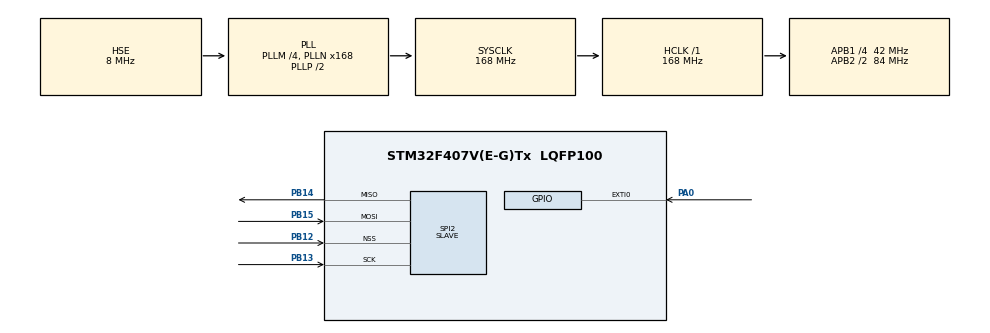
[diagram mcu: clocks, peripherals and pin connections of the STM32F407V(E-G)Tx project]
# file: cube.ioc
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Dma.Request0=SPI2_RX
Dma.Request1=SPI2_TX
Dma.SPI2_RX.0.Direction=DMA_PERIPH_TO_MEMORY
Dma.SPI2_RX.0.FIFOMode=DMA_FIFOMODE_DISABLE
Dma.SPI2_RX.0.Instance=DMA1_Stream3
Dma.SPI2_RX.0.MemDataAlignment=DMA_MDATAALIGN_BYTE
Dma.SPI2_RX.0.MemInc=DMA_MINC_ENABLE
Dma.SPI2_RX.0.Mode=DMA_NORMAL
Dma.SPI2_RX.0.PeriphDataAlignment=DMA_PDATAALIGN_BYTE
Dma.SPI2_RX.0.PeriphInc=DMA_PINC_DISABLE
Dma.SPI2_RX.0.Priority=DMA_PRIORITY_LOW
Dma.SPI2_TX.1.Direction=DMA_MEMORY_TO_PERIPH
Dma.SPI2_TX.1.FIFOMode=DMA_FIFOMODE_DISABLE
Dma.SPI2_TX.1.Instance=DMA1_Stream4
Dma.SPI2_TX.1.MemDataAlignment=DMA_MDATAALIGN_BYTE
Dma.SPI2_TX.1.MemInc=DMA_MINC_ENABLE
Dma.SPI2_TX.1.Mode=DMA_NORMAL
Dma.SPI2_TX.1.PeriphDataAlignment=DMA_PDATAALIGN_BYTE
Dma.SPI2_TX.1.PeriphInc=DMA_PINC_DISABLE
Dma.SPI2_TX.1.Priority=DMA_PRIORITY_LOW
Mcu.Family=STM32F4
Mcu.Name=STM32F407V(E-G)Tx
Mcu.Package=LQFP100
NVIC.DMA1_Stream3_IRQn=true\:0\:0\:false\:false\:true\:false\:true
NVIC.DMA1_Stream4_IRQn=true\:0\:0\:false\:false\:true\:false\:true
NVIC.EXTI0_IRQn=true\:0\:0\:false\:false\:true\:true\:true
NVIC.PriorityGroup=NVIC_PRIORITYGROUP_4
NVIC.SPI2_IRQn=true\:0\:0\:false\:false\:true\:true\:true
PA0-WKUP.Signal=GPXTI0
PA13.Mode=Serial_Wire
PA13.Signal=SYS_JTMS-SWDIO
PA14.Mode=Serial_Wire
PA14.Signal=SYS_JTCK-SWCLK
PB12.Mode=NSS_Signal_Hard_Input
PB12.Signal=SPI2_NSS
PB13.Mode=Full_Duplex_Slave
PB13.Signal=SPI2_SCK
PB14.Mode=Full_Duplex_Slave
PB14.Signal=SPI2_MISO
PB15.Mode=Full_Duplex_Slave
PB15.Signal=SPI2_MOSI
PH0-OSC_IN.Mode=HSE-External-Oscillator
PH0-OSC_IN.Signal=RCC_OSC_IN
PH1-OSC_OUT.Mode=HSE-External-Oscillator
PH1-OSC_OUT.Signal=RCC_OSC_OUT
ProjectManager.HeapSize=0x200
ProjectManager.StackSize=0x400
ProjectManager.TargetToolchain=STM32CubeIDE
RCC.48MHZClocksFreq_Value=84000000
RCC.AHBFreq_Value=168000000
RCC.APB1CLKDivider=RCC_HCLK_DIV4
RCC.APB1Freq_Value=42000000
RCC.APB1TimFreq_Value=84000000
RCC.APB2CLKDivider=RCC_HCLK_DIV2
RCC.APB2Freq_Value=84000000
RCC.APB2TimFreq_Value=168000000
RCC.CortexFreq_Value=168000000
RCC.HCLKFreq_Value=168000000
RCC.HSE_VALUE=8000000
RCC.HSI_VALUE=16000000
RCC.LSE_VALUE=32768
RCC.PLLM=4
RCC.PLLN=168
RCC.PLLSourceVirtual=RCC_PLLSOURCE_HSE
RCC.SYSCLKFreq_VALUE=168000000
RCC.SYSCLKSource=RCC_SYSCLKSOURCE_PLLCLK
RCC.VCOOutputFreq_Value=336000000
SPI2.CLKPolarity=SPI_POLARITY_HIGH
SPI2.Direction=SPI_DIRECTION_2LINES
SPI2.Mode=SPI_MODE_SLAVE
SPI2.VirtualNSS=VM_NSSHARD
SPI2.VirtualType=VM_SLAVE
board=custom

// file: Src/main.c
/* USER CODE BEGIN Header */
/**
  ******************************************************************************
  * @file           : main.c
  * @brief          : Main program body
  ******************************************************************************
  * @attention
  *
  * <h2><center>&copy; Copyright (c) 2019 STMicroelectronics.
  * All rights reserved.</center></h2>
  *
  * This software component is licensed by ST under BSD 3-Clause license,
  * the "License"; You may not use this file except in compliance with the
  * License. You may obtain a copy of the License at:
  *                        opensource.org/licenses/BSD-3-Clause
  *
  ******************************************************************************
  */
/* USER CODE END Header */

#include "main.h"

/* USER CODE BEGIN Includes */

#include "ctl.h"
#include "exti.h"
#include "spi2.h"

/* USER CODE END Includes */

SPI_HandleTypeDef hspi2;
DMA_HandleTypeDef hdma_spi2_rx;
DMA_HandleTypeDef hdma_spi2_tx;

void SystemClock_Config(void);
static void MX_GPIO_Init(void);
static void MX_DMA_Init(void);
static void MX_SPI2_Init(void);

int main(void)
{

  /* MCU Configuration--------------------------------------------------------*/

  /* Reset of all peripherals, Initializes the Flash interface and the Systick. */
  HAL_Init();

  /* Configure the system clock */
  SystemClock_Config();

  /* Initialize all configured peripherals */
  MX_GPIO_Init();
  MX_DMA_Init();
  MX_SPI2_Init();
  /* USER CODE BEGIN 2 */

  SPI2_Ini();
  CTL_Ini();

  /* USER CODE END 2 */

  /* Infinite loop */
  while (1)
  {

    /* USER CODE BEGIN 3 */

	  CTL_Main();
  }
  /* USER CODE END 3 */
}

void SystemClock_Config(void)
{
  RCC_OscInitTypeDef RCC_OscInitStruct = {0};
  RCC_ClkInitTypeDef RCC_ClkInitStruct = {0};

  /** Configure the main internal regulator output voltage
  */
  __HAL_RCC_PWR_CLK_ENABLE();
  __HAL_PWR_VOLTAGESCALING_CONFIG(PWR_REGULATOR_VOLTAGE_SCALE1);
  /** Initializes the CPU, AHB and APB busses clocks
  */
  RCC_OscInitStruct.OscillatorType = RCC_OSCILLATORTYPE_HSE;
  RCC_OscInitStruct.HSEState = RCC_HSE_ON;
  RCC_OscInitStruct.PLL.PLLState = RCC_PLL_ON;
  RCC_OscInitStruct.PLL.PLLSource = RCC_PLLSOURCE_HSE;
  RCC_OscInitStruct.PLL.PLLM = 4;
  RCC_OscInitStruct.PLL.PLLN = 168;
  RCC_OscInitStruct.PLL.PLLP = RCC_PLLP_DIV2;
  RCC_OscInitStruct.PLL.PLLQ = 4;
  if (HAL_RCC_OscConfig(&RCC_OscInitStruct) != HAL_OK)
  {
    Error_Handler();
  }
  /** Initializes the CPU, AHB and APB busses clocks
  */
  RCC_ClkInitStruct.ClockType = RCC_CLOCKTYPE_HCLK|RCC_CLOCKTYPE_SYSCLK
                              |RCC_CLOCKTYPE_PCLK1|RCC_CLOCKTYPE_PCLK2;
  RCC_ClkInitStruct.SYSCLKSource = RCC_SYSCLKSOURCE_PLLCLK;
  RCC_ClkInitStruct.AHBCLKDivider = RCC_SYSCLK_DIV1;
  RCC_ClkInitStruct.APB1CLKDivider = RCC_HCLK_DIV4;
  RCC_ClkInitStruct.APB2CLKDivider = RCC_HCLK_DIV2;

  if (HAL_RCC_ClockConfig(&RCC_ClkInitStruct, FLASH_LATENCY_5) != HAL_OK)
  {
    Error_Handler();
  }
}

static void MX_SPI2_Init(void)
{

  /* SPI2 parameter configuration*/
  hspi2.Instance = SPI2;
  hspi2.Init.Mode = SPI_MODE_SLAVE;
  hspi2.Init.Direction = SPI_DIRECTION_2LINES;
  hspi2.Init.DataSize = SPI_DATASIZE_8BIT;
  hspi2.Init.CLKPolarity = SPI_POLARITY_HIGH;
  hspi2.Init.CLKPhase = SPI_PHASE_1EDGE;
  hspi2.Init.NSS = SPI_NSS_HARD_INPUT;
  hspi2.Init.FirstBit = SPI_FIRSTBIT_MSB;
  hspi2.Init.TIMode = SPI_TIMODE_DISABLE;
  hspi2.Init.CRCCalculation = SPI_CRCCALCULATION_DISABLE;
  hspi2.Init.CRCPolynomial = 10;
  if (HAL_SPI_Init(&hspi2) != HAL_OK)
  {
    Error_Handler();
  }

}

static void MX_DMA_Init(void)
{
  /* DMA controller clock enable */
  __HAL_RCC_DMA1_CLK_ENABLE();

  /* DMA interrupt init */
  /* DMA1_Stream3_IRQn interrupt configuration */
  HAL_NVIC_SetPriority(DMA1_Stream3_IRQn, 0, 0);
  HAL_NVIC_EnableIRQ(DMA1_Stream3_IRQn);
  /* DMA1_Stream4_IRQn interrupt configuration */
  HAL_NVIC_SetPriority(DMA1_Stream4_IRQn, 0, 0);
  HAL_NVIC_EnableIRQ(DMA1_Stream4_IRQn);

}

static void MX_GPIO_Init(void)
{
  GPIO_InitTypeDef GPIO_InitStruct = {0};

  /* GPIO Ports Clock Enable */
  __HAL_RCC_GPIOH_CLK_ENABLE();
  __HAL_RCC_GPIOA_CLK_ENABLE();
  __HAL_RCC_GPIOB_CLK_ENABLE();

  /*Configure GPIO pin : PA0 */
  GPIO_InitStruct.Pin = GPIO_PIN_0;
  GPIO_InitStruct.Mode = GPIO_MODE_IT_RISING;
  GPIO_InitStruct.Pull = GPIO_NOPULL;
  HAL_GPIO_Init(GPIOA, &GPIO_InitStruct);

  /* EXTI interrupt init*/
  HAL_NVIC_SetPriority(EXTI0_IRQn, 0, 0);
  HAL_NVIC_EnableIRQ(EXTI0_IRQn);

}

/* USER CODE BEGIN 4 */

/******************************************************************************
*  Function Name  :
*  Description    :
*  Parameter(s)   :
*  Return Value   :
******************************************************************************/

/*
void SPIx_DMA_RX_IRQHandler(void)
{
  HAL_DMA_IRQHandler(hspi2.hdmarx);
}
*/

/******************************************************************************
*  Function Name  :
*  Description    :
*  Parameter(s)   :
*  Return Value   :
******************************************************************************/

void HAL_SPI_TxRxCpltCallback(SPI_HandleTypeDef *hspi)
{

	if(hspi->Instance==SPI2)
	{
		HAL_SPI_TransmitReceive_DMA(&hspi2, SPI2_TxBuf, SPI2_RxBuf, SPI2_TXRX_BUFFER_SIZE);

	}
}

/******************************************************************************
*  Function Name  :
*  Description    :
*  Parameter(s)   :
*  Return Value   :
******************************************************************************/

void HAL_GPIO_EXTI_Callback(uint16_t GPIO_Pin)
{

	if (GPIO_Pin == GPIO_PIN_0)
	{
			TUINT8 u8Temp;
			u8Temp = 0;
	}
	else
	{

	}

}

/* USER CODE END 4 */

void Error_Handler(void)
{
}

/************************ (C) COPYRIGHT STMicroelectronics *****END OF FILE****/
